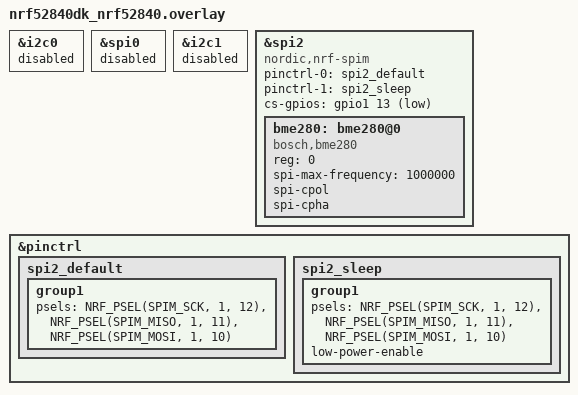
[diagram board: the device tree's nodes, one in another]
/* STEP 2.1 - Add the SPI peripheral to spi1 */
&i2c0 {status = "disabled";};
&spi0 {status = "disabled";};
&i2c1 {status = "disabled";};

&spi2 {
	compatible = "nordic,nrf-spim";
	status = "okay";
	pinctrl-0 = <&spi2_default>;
	pinctrl-1 = <&spi2_sleep>;
	pinctrl-names = "default", "sleep";
	cs-gpios = <&gpio1 13 GPIO_ACTIVE_LOW>;
	bme280: bme280@0 {
		compatible = "bosch,bme280";
		reg = <0>;
		spi-max-frequency = <1000000>;
		spi-cpol;
		spi-cpha;
	};
};

/* STEP 2.2 - Change the pin configuration */
&pinctrl {
    spi2_default: spi2_default {
        group1 {
            psels = <NRF_PSEL(SPIM_SCK, 1, 12)>,
                    <NRF_PSEL(SPIM_MISO, 1, 11)>,
                    <NRF_PSEL(SPIM_MOSI, 1, 10)>;
        };
    };

    spi2_sleep: spi2_sleep {
        group1 {
            psels = <NRF_PSEL(SPIM_SCK, 1, 12)>,
                    <NRF_PSEL(SPIM_MISO, 1, 11)>,
                    <NRF_PSEL(SPIM_MOSI, 1, 10)>;
            low-power-enable;
        };
    };
};
